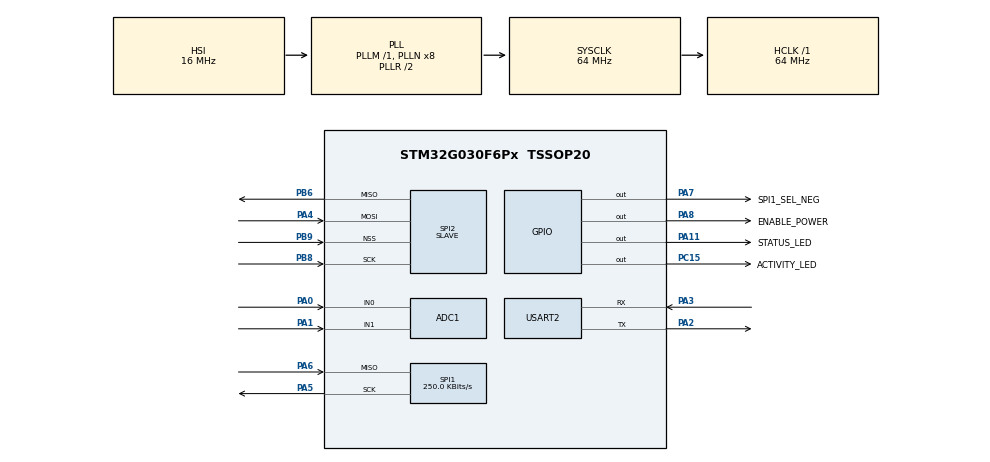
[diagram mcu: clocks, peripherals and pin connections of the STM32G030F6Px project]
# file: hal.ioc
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ADC1.Channel-0\#ChannelRegularConversion=ADC_CHANNEL_1
ADC1.ContinuousConvMode=ENABLE
ADC1.DiscontinuousConvMode=DISABLE
ADC1.ExternalTrigConv=ADC_EXTERNALTRIG_T3_TRGO
ADC1.NbrOfConversion=1
ADC1.NbrOfConversionFlag=1
ADC1.Rank-0\#ChannelRegularConversion=1
ADC1.SamplingTime-0\#ChannelRegularConversion=ADC_SAMPLINGTIME_COMMON_1
ADC1.SelectedChannel=ADC_CHANNEL_0|ADC_CHANNEL_1
ADC1.master=1
Mcu.Family=STM32G0
Mcu.Name=STM32G030F6Px
Mcu.Package=TSSOP20
NVIC.ADC1_IRQn=true\:0\:0\:false\:false\:true\:true\:true
NVIC.SPI1_IRQn=true\:0\:0\:false\:false\:true\:true\:true
NVIC.SPI2_IRQn=true\:0\:0\:false\:false\:true\:true\:true
NVIC.TIM3_IRQn=true\:0\:0\:false\:false\:true\:true\:true
PA0.Mode=IN0
PA0.Signal=ADC1_IN0
PA1.Mode=IN1
PA1.Signal=ADC1_IN1
PA11\ [PA9].GPIO_Label=STATUS_LED
PA11\ [PA9].PinState=GPIO_PIN_SET
PA11\ [PA9].Signal=GPIO_Output
PA13.Mode=Serial_Wire
PA13.Signal=SYS_SWDIO
PA14-BOOT0.Mode=Serial_Wire
PA14-BOOT0.Signal=SYS_SWCLK
PA2.Mode=Asynchronous
PA2.Signal=USART2_TX
PA3.Mode=Asynchronous
PA3.Signal=USART2_RX
PA4.Mode=Full_Duplex_Slave
PA4.Signal=SPI2_MOSI
PA5.Mode=RX_Only_Simplex_Unidirect_Master
PA5.Signal=SPI1_SCK
PA6.Mode=RX_Only_Simplex_Unidirect_Master
PA6.Signal=SPI1_MISO
PA7.GPIO_Label=SPI1_SEL_NEG
PA7.PinState=GPIO_PIN_SET
PA7.Signal=GPIO_Output
PA8.GPIO_Label=ENABLE_POWER
PA8.GPIO_PuPd=GPIO_PULLDOWN
PA8.Signal=GPIO_Output
PB6.Mode=Full_Duplex_Slave
PB6.Signal=SPI2_MISO
PB8.Mode=Full_Duplex_Slave
PB8.Signal=SPI2_SCK
PB9.Mode=NSS_Signal_Hard_Input
PB9.Signal=SPI2_NSS
PC15-OSC32_OUT\ (PC15).GPIO_Label=ACTIVITY_LED
PC15-OSC32_OUT\ (PC15).PinState=GPIO_PIN_SET
PC15-OSC32_OUT\ (PC15).Signal=GPIO_Output
ProjectManager.HeapSize=0x200
ProjectManager.StackSize=0x400
ProjectManager.TargetToolchain=Makefile
RCC.ADCFreq_Value=64000000
RCC.AHBFreq_Value=64000000
RCC.CortexFreq_Value=64000000
RCC.EXTERNAL_CLOCK_VALUE=12288000
RCC.HCLKFreq_Value=64000000
RCC.HSE_VALUE=8000000
RCC.HSI_VALUE=16000000
RCC.LSE_VALUE=32768
RCC.SYSCLKFreq_VALUE=64000000
RCC.SYSCLKSource=RCC_SYSCLKSOURCE_PLLCLK
RCC.VCOOutputFreq_Value=128000000
RCC.VDD_VALUE=3
SPI1.BaudRatePrescaler=SPI_BAUDRATEPRESCALER_256
SPI1.CalculateBaudRate=250.0 KBits/s
SPI1.DataSize=SPI_DATASIZE_16BIT
SPI1.Direction=SPI_DIRECTION_2LINES_RXONLY
SPI1.Mode=SPI_MODE_MASTER
SPI1.VirtualType=VM_MASTER
SPI2.DataSize=SPI_DATASIZE_16BIT
SPI2.Direction=SPI_DIRECTION_2LINES
SPI2.FirstBit=SPI_FIRSTBIT_MSB
SPI2.Mode=SPI_MODE_SLAVE
SPI2.VirtualNSS=VM_NSSHARD
SPI2.VirtualType=VM_SLAVE
TIM1.AutoReloadPreload=TIM_AUTORELOAD_PRELOAD_ENABLE
TIM1.CounterMode=TIM_COUNTERMODE_UP
TIM1.Period=32000 -1
TIM1.Prescaler=2
TIM3.AutoReloadPreload=TIM_AUTORELOAD_PRELOAD_ENABLE
TIM3.Channel-PWM\ Generation1\ No\ Output=TIM_CHANNEL_1
TIM3.Period=40000
TIM3.Prescaler=400
TIM3.TIM_MasterOutputTrigger=TIM_TRGO_UPDATE
USART2.VirtualMode-Asynchronous=VM_ASYNC
VP_TIM1_VS_OPM.Mode=OPM_bit
VP_TIM3_VS_ClockSourceINT.Mode=Internal
VP_TIM3_VS_no_output1.Mode=PWM Generation1 No Output
board=custom

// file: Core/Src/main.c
/* USER CODE BEGIN Header */
/**
	******************************************************************************
	* @file           : main.c
	* @brief          : Main program body
	******************************************************************************
	* @attention
	*
	* <h2><center>&copy; Copyright (c) 2021 STMicroelectronics.
	* All rights reserved.</center></h2>
	*
	* This software component is licensed by ST under BSD 3-Clause license,
	* the "License"; You may not use this file except in compliance with the
	* License. You may obtain a copy of the License at:
	*                        opensource.org/licenses/BSD-3-Clause
	*
	******************************************************************************
	*/
/* USER CODE END Header */
#include "main.h"

/* USER CODE BEGIN Includes */
extern void user_main();
/* USER CODE END Includes */

ADC_HandleTypeDef hadc1;

SPI_HandleTypeDef hspi1;
SPI_HandleTypeDef hspi2;

TIM_HandleTypeDef htim1;
TIM_HandleTypeDef htim3;

UART_HandleTypeDef huart2;

void SystemClock_Config(void);
static void MX_GPIO_Init(void);
static void MX_ADC1_Init(void);
static void MX_SPI1_Init(void);
static void MX_SPI2_Init(void);
static void MX_TIM1_Init(void);
static void MX_USART2_UART_Init(void);
static void MX_TIM3_Init(void);

/* USER CODE BEGIN 0 */
extern void user_main();
/* USER CODE END 0 */

int main(void)
{

  /* MCU Configuration--------------------------------------------------------*/

  /* Reset of all peripherals, Initializes the Flash interface and the Systick. */
  HAL_Init();

  /* Configure the system clock */
  SystemClock_Config();

  /* Initialize all configured peripherals */
  MX_GPIO_Init();
  MX_ADC1_Init();
  MX_SPI1_Init();
  MX_SPI2_Init();
  MX_TIM1_Init();
  MX_USART2_UART_Init();
  MX_TIM3_Init();

  /* Infinite loop */
  /* USER CODE BEGIN WHILE */
  user_main();
    /* USER CODE END WHILE */

}

void SystemClock_Config(void)
{
  RCC_OscInitTypeDef RCC_OscInitStruct = {0};
  RCC_ClkInitTypeDef RCC_ClkInitStruct = {0};
  RCC_PeriphCLKInitTypeDef PeriphClkInit = {0};

  /** Configure the main internal regulator output voltage
  */
  HAL_PWREx_ControlVoltageScaling(PWR_REGULATOR_VOLTAGE_SCALE1);
  /** Initializes the RCC Oscillators according to the specified parameters
  * in the RCC_OscInitTypeDef structure.
  */
  RCC_OscInitStruct.OscillatorType = RCC_OSCILLATORTYPE_HSI;
  RCC_OscInitStruct.HSIState = RCC_HSI_ON;
  RCC_OscInitStruct.HSIDiv = RCC_HSI_DIV1;
  RCC_OscInitStruct.HSICalibrationValue = RCC_HSICALIBRATION_DEFAULT;
  RCC_OscInitStruct.PLL.PLLState = RCC_PLL_ON;
  RCC_OscInitStruct.PLL.PLLSource = RCC_PLLSOURCE_HSI;
  RCC_OscInitStruct.PLL.PLLM = RCC_PLLM_DIV1;
  RCC_OscInitStruct.PLL.PLLN = 8;
  RCC_OscInitStruct.PLL.PLLP = RCC_PLLP_DIV2;
  RCC_OscInitStruct.PLL.PLLR = RCC_PLLR_DIV2;
  if (HAL_RCC_OscConfig(&RCC_OscInitStruct) != HAL_OK)
  {
    Error_Handler();
  }
  /** Initializes the CPU, AHB and APB buses clocks
  */
  RCC_ClkInitStruct.ClockType = RCC_CLOCKTYPE_HCLK|RCC_CLOCKTYPE_SYSCLK
                              |RCC_CLOCKTYPE_PCLK1;
  RCC_ClkInitStruct.SYSCLKSource = RCC_SYSCLKSOURCE_PLLCLK;
  RCC_ClkInitStruct.AHBCLKDivider = RCC_SYSCLK_DIV1;
  RCC_ClkInitStruct.APB1CLKDivider = RCC_HCLK_DIV1;

  if (HAL_RCC_ClockConfig(&RCC_ClkInitStruct, FLASH_LATENCY_2) != HAL_OK)
  {
    Error_Handler();
  }
  /** Initializes the peripherals clocks
  */
  PeriphClkInit.PeriphClockSelection = RCC_PERIPHCLK_ADC;
  PeriphClkInit.AdcClockSelection = RCC_ADCCLKSOURCE_SYSCLK;
  if (HAL_RCCEx_PeriphCLKConfig(&PeriphClkInit) != HAL_OK)
  {
    Error_Handler();
  }
}

static void MX_ADC1_Init(void)
{

  ADC_ChannelConfTypeDef sConfig = {0};

  /** Configure the global features of the ADC (Clock, Resolution, Data Alignment and number of conversion)
  */
  hadc1.Instance = ADC1;
  hadc1.Init.ClockPrescaler = ADC_CLOCK_SYNC_PCLK_DIV2;
  hadc1.Init.Resolution = ADC_RESOLUTION_12B;
  hadc1.Init.DataAlign = ADC_DATAALIGN_RIGHT;
  hadc1.Init.ScanConvMode = ADC_SCAN_DISABLE;
  hadc1.Init.EOCSelection = ADC_EOC_SINGLE_CONV;
  hadc1.Init.LowPowerAutoWait = DISABLE;
  hadc1.Init.LowPowerAutoPowerOff = DISABLE;
  hadc1.Init.ContinuousConvMode = ENABLE;
  hadc1.Init.NbrOfConversion = 1;
  hadc1.Init.DiscontinuousConvMode = DISABLE;
  hadc1.Init.ExternalTrigConv = ADC_EXTERNALTRIG_T3_TRGO;
  hadc1.Init.ExternalTrigConvEdge = ADC_EXTERNALTRIGCONVEDGE_RISING;
  hadc1.Init.DMAContinuousRequests = DISABLE;
  hadc1.Init.Overrun = ADC_OVR_DATA_PRESERVED;
  hadc1.Init.SamplingTimeCommon1 = ADC_SAMPLETIME_1CYCLE_5;
  hadc1.Init.SamplingTimeCommon2 = ADC_SAMPLETIME_1CYCLE_5;
  hadc1.Init.OversamplingMode = DISABLE;
  hadc1.Init.TriggerFrequencyMode = ADC_TRIGGER_FREQ_HIGH;
  if (HAL_ADC_Init(&hadc1) != HAL_OK)
  {
    Error_Handler();
  }
  /** Configure Regular Channel
  */
  sConfig.Channel = ADC_CHANNEL_1;
  sConfig.Rank = ADC_REGULAR_RANK_1;
  sConfig.SamplingTime = ADC_SAMPLINGTIME_COMMON_1;
  if (HAL_ADC_ConfigChannel(&hadc1, &sConfig) != HAL_OK)
  {
    Error_Handler();
  }

}

static void MX_SPI1_Init(void)
{

  /* SPI1 parameter configuration*/
  hspi1.Instance = SPI1;
  hspi1.Init.Mode = SPI_MODE_MASTER;
  hspi1.Init.Direction = SPI_DIRECTION_2LINES_RXONLY;
  hspi1.Init.DataSize = SPI_DATASIZE_16BIT;
  hspi1.Init.CLKPolarity = SPI_POLARITY_LOW;
  hspi1.Init.CLKPhase = SPI_PHASE_1EDGE;
  hspi1.Init.NSS = SPI_NSS_SOFT;
  hspi1.Init.BaudRatePrescaler = SPI_BAUDRATEPRESCALER_128;
  hspi1.Init.FirstBit = SPI_FIRSTBIT_MSB;
  hspi1.Init.TIMode = SPI_TIMODE_DISABLE;
  hspi1.Init.CRCCalculation = SPI_CRCCALCULATION_DISABLE;
  hspi1.Init.CRCPolynomial = 7;
  hspi1.Init.CRCLength = SPI_CRC_LENGTH_DATASIZE;
  hspi1.Init.NSSPMode = SPI_NSS_PULSE_ENABLE;
  if (HAL_SPI_Init(&hspi1) != HAL_OK)
  {
    Error_Handler();
  }

}

static void MX_SPI2_Init(void)
{

  /* SPI2 parameter configuration*/
  hspi2.Instance = SPI2;
  hspi2.Init.Mode = SPI_MODE_SLAVE;
  hspi2.Init.Direction = SPI_DIRECTION_2LINES;
  hspi2.Init.DataSize = SPI_DATASIZE_16BIT;
  hspi2.Init.CLKPolarity = SPI_POLARITY_LOW;
  hspi2.Init.CLKPhase = SPI_PHASE_1EDGE;
  hspi2.Init.NSS = SPI_NSS_HARD_INPUT;
  hspi2.Init.FirstBit = SPI_FIRSTBIT_MSB;
  hspi2.Init.TIMode = SPI_TIMODE_DISABLE;
  hspi2.Init.CRCCalculation = SPI_CRCCALCULATION_DISABLE;
  hspi2.Init.CRCPolynomial = 7;
  hspi2.Init.CRCLength = SPI_CRC_LENGTH_DATASIZE;
  hspi2.Init.NSSPMode = SPI_NSS_PULSE_DISABLE;
  if (HAL_SPI_Init(&hspi2) != HAL_OK)
  {
    Error_Handler();
  }

}

static void MX_TIM1_Init(void)
{

  TIM_MasterConfigTypeDef sMasterConfig = {0};

  htim1.Instance = TIM1;
  htim1.Init.Prescaler = 2;
  htim1.Init.CounterMode = TIM_COUNTERMODE_UP;
  htim1.Init.Period = 32000 -1;
  htim1.Init.ClockDivision = TIM_CLOCKDIVISION_DIV1;
  htim1.Init.RepetitionCounter = 0;
  htim1.Init.AutoReloadPreload = TIM_AUTORELOAD_PRELOAD_ENABLE;
  if (HAL_TIM_OnePulse_Init(&htim1, TIM_OPMODE_SINGLE) != HAL_OK)
  {
    Error_Handler();
  }
  sMasterConfig.MasterOutputTrigger = TIM_TRGO_RESET;
  sMasterConfig.MasterOutputTrigger2 = TIM_TRGO2_RESET;
  sMasterConfig.MasterSlaveMode = TIM_MASTERSLAVEMODE_DISABLE;
  if (HAL_TIMEx_MasterConfigSynchronization(&htim1, &sMasterConfig) != HAL_OK)
  {
    Error_Handler();
  }

}

static void MX_TIM3_Init(void)
{

  TIM_ClockConfigTypeDef sClockSourceConfig = {0};
  TIM_MasterConfigTypeDef sMasterConfig = {0};
  TIM_OC_InitTypeDef sConfigOC = {0};

  htim3.Instance = TIM3;
  htim3.Init.Prescaler = 400;
  htim3.Init.CounterMode = TIM_COUNTERMODE_UP;
  htim3.Init.Period = 40000;
  htim3.Init.ClockDivision = TIM_CLOCKDIVISION_DIV1;
  htim3.Init.AutoReloadPreload = TIM_AUTORELOAD_PRELOAD_ENABLE;
  if (HAL_TIM_Base_Init(&htim3) != HAL_OK)
  {
    Error_Handler();
  }
  sClockSourceConfig.ClockSource = TIM_CLOCKSOURCE_INTERNAL;
  if (HAL_TIM_ConfigClockSource(&htim3, &sClockSourceConfig) != HAL_OK)
  {
    Error_Handler();
  }
  if (HAL_TIM_PWM_Init(&htim3) != HAL_OK)
  {
    Error_Handler();
  }
  sMasterConfig.MasterOutputTrigger = TIM_TRGO_UPDATE;
  sMasterConfig.MasterSlaveMode = TIM_MASTERSLAVEMODE_DISABLE;
  if (HAL_TIMEx_MasterConfigSynchronization(&htim3, &sMasterConfig) != HAL_OK)
  {
    Error_Handler();
  }
  sConfigOC.OCMode = TIM_OCMODE_PWM1;
  sConfigOC.Pulse = 0;
  sConfigOC.OCPolarity = TIM_OCPOLARITY_HIGH;
  sConfigOC.OCFastMode = TIM_OCFAST_DISABLE;
  if (HAL_TIM_PWM_ConfigChannel(&htim3, &sConfigOC, TIM_CHANNEL_1) != HAL_OK)
  {
    Error_Handler();
  }

}

static void MX_USART2_UART_Init(void)
{

  huart2.Instance = USART2;
  huart2.Init.BaudRate = 115200;
  huart2.Init.WordLength = UART_WORDLENGTH_8B;
  huart2.Init.StopBits = UART_STOPBITS_1;
  huart2.Init.Parity = UART_PARITY_NONE;
  huart2.Init.Mode = UART_MODE_TX_RX;
  huart2.Init.HwFlowCtl = UART_HWCONTROL_NONE;
  huart2.Init.OverSampling = UART_OVERSAMPLING_16;
  huart2.Init.OneBitSampling = UART_ONE_BIT_SAMPLE_DISABLE;
  huart2.Init.ClockPrescaler = UART_PRESCALER_DIV1;
  huart2.AdvancedInit.AdvFeatureInit = UART_ADVFEATURE_NO_INIT;
  if (HAL_UART_Init(&huart2) != HAL_OK)
  {
    Error_Handler();
  }

}

static void MX_GPIO_Init(void)
{
  GPIO_InitTypeDef GPIO_InitStruct = {0};

  /* GPIO Ports Clock Enable */
  __HAL_RCC_GPIOB_CLK_ENABLE();
  __HAL_RCC_GPIOC_CLK_ENABLE();
  __HAL_RCC_GPIOA_CLK_ENABLE();

  /*Configure GPIO pin Output Level */
  HAL_GPIO_WritePin(ACTIVITY_LED_GPIO_Port, ACTIVITY_LED_Pin, GPIO_PIN_SET);

  /*Configure GPIO pin Output Level */
  HAL_GPIO_WritePin(GPIOA, SPI1_SEL_NEG_Pin|STATUS_LED_Pin, GPIO_PIN_SET);

  /*Configure GPIO pin Output Level */
  HAL_GPIO_WritePin(ENABLE_POWER_GPIO_Port, ENABLE_POWER_Pin, GPIO_PIN_RESET);

  /*Configure GPIO pin : ACTIVITY_LED_Pin */
  GPIO_InitStruct.Pin = ACTIVITY_LED_Pin;
  GPIO_InitStruct.Mode = GPIO_MODE_OUTPUT_PP;
  GPIO_InitStruct.Pull = GPIO_NOPULL;
  GPIO_InitStruct.Speed = GPIO_SPEED_FREQ_LOW;
  HAL_GPIO_Init(ACTIVITY_LED_GPIO_Port, &GPIO_InitStruct);

  /*Configure GPIO pins : SPI1_SEL_NEG_Pin STATUS_LED_Pin */
  GPIO_InitStruct.Pin = SPI1_SEL_NEG_Pin|STATUS_LED_Pin;
  GPIO_InitStruct.Mode = GPIO_MODE_OUTPUT_PP;
  GPIO_InitStruct.Pull = GPIO_NOPULL;
  GPIO_InitStruct.Speed = GPIO_SPEED_FREQ_LOW;
  HAL_GPIO_Init(GPIOA, &GPIO_InitStruct);

  /*Configure GPIO pin : ENABLE_POWER_Pin */
  GPIO_InitStruct.Pin = ENABLE_POWER_Pin;
  GPIO_InitStruct.Mode = GPIO_MODE_OUTPUT_PP;
  GPIO_InitStruct.Pull = GPIO_PULLDOWN;
  GPIO_InitStruct.Speed = GPIO_SPEED_FREQ_LOW;
  HAL_GPIO_Init(ENABLE_POWER_GPIO_Port, &GPIO_InitStruct);

}

void Error_Handler(void)
{
	__disable_irq();
	while (1)
	{
	}
}

/************************ (C) COPYRIGHT STMicroelectronics *****END OF FILE****/
